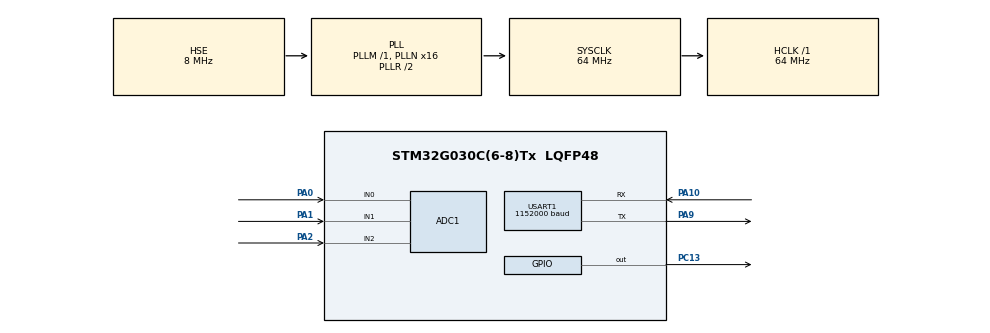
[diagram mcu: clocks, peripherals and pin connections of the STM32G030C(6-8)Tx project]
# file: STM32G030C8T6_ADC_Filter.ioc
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ADC1.ContinuousConvMode=ENABLE
ADC1.DMAContinuousRequests=ENABLE
ADC1.NbrOfConversion=1
ADC1.NbrOfConversionFlag=0
ADC1.SamplingTimeCommon1=ADC_SAMPLETIME_79CYCLES_5
ADC1.SelectedChannel=ADC_CHANNEL_0|ADC_CHANNEL_1|ADC_CHANNEL_2|ADC_CHANNEL_TEMPSENSOR
ADC1.Sequencer=NOT_FULLY_CONFIGURABLE
ADC1.master=1
Dma.ADC1.0.Direction=DMA_PERIPH_TO_MEMORY
Dma.ADC1.0.EventEnable=DISABLE
Dma.ADC1.0.Instance=DMA1_Channel1
Dma.ADC1.0.MemDataAlignment=DMA_MDATAALIGN_WORD
Dma.ADC1.0.MemInc=DMA_MINC_ENABLE
Dma.ADC1.0.Mode=DMA_CIRCULAR
Dma.ADC1.0.PeriphDataAlignment=DMA_PDATAALIGN_WORD
Dma.ADC1.0.PeriphInc=DMA_PINC_DISABLE
Dma.ADC1.0.Polarity=HAL_DMAMUX_REQ_GEN_RISING
Dma.ADC1.0.Priority=DMA_PRIORITY_LOW
Dma.ADC1.0.RequestNumber=1
Dma.ADC1.0.SignalID=NONE
Dma.ADC1.0.SyncEnable=DISABLE
Dma.ADC1.0.SyncPolarity=HAL_DMAMUX_SYNC_NO_EVENT
Dma.ADC1.0.SyncRequestNumber=1
Dma.ADC1.0.SyncSignalID=NONE
Dma.Request0=ADC1
Mcu.Family=STM32G0
Mcu.Name=STM32G030C(6-8)Tx
Mcu.Package=LQFP48
NVIC.ADC1_IRQn=true\:0\:0\:false\:false\:true\:true\:true\:true
NVIC.DMA1_Channel1_IRQn=true\:0\:0\:false\:false\:true\:false\:true\:true
PA0.Mode=IN0
PA0.Signal=ADC1_IN0
PA1.Mode=IN1
PA1.Signal=ADC1_IN1
PA10.Mode=Asynchronous
PA10.Signal=USART1_RX
PA13.Mode=Serial_Wire
PA13.Signal=SYS_SWDIO
PA14-BOOT0.Mode=Serial_Wire
PA14-BOOT0.Signal=SYS_SWCLK
PA2.Mode=IN2
PA2.Signal=ADC1_IN2
PA9.Mode=Asynchronous
PA9.Signal=USART1_TX
PC13.PinState=GPIO_PIN_SET
PC13.Signal=GPIO_Output
PF0-OSC_IN\ (PF0).Mode=HSE-External-Oscillator
PF0-OSC_IN\ (PF0).Signal=RCC_OSC_IN
PF1-OSC_OUT\ (PF1).Mode=HSE-External-Oscillator
PF1-OSC_OUT\ (PF1).Signal=RCC_OSC_OUT
ProjectManager.HeapSize=0x200
ProjectManager.StackSize=0x400
ProjectManager.TargetToolchain=Makefile
RCC.ADCFreq_Value=64000000
RCC.AHBFreq_Value=64000000
RCC.CortexFreq_Value=64000000
RCC.DATA_CACHE_ENABLE=1
RCC.EXTERNAL_CLOCK_VALUE=12288000
RCC.HCLKFreq_Value=64000000
RCC.HSE_VALUE=8000000
RCC.HSI_VALUE=16000000
RCC.INSTRUCTION_CACHE_ENABLE=1
RCC.LSE_VALUE=32768
RCC.PLLN=16
RCC.PLLSourceVirtual=RCC_PLLSOURCE_HSE
RCC.PREFETCH_ENABLE=1
RCC.SYSCLKFreq_VALUE=64000000
RCC.SYSCLKSource=RCC_SYSCLKSOURCE_PLLCLK
RCC.VCOOutputFreq_Value=128000000
USART1.BaudRate=1152000
USART1.VirtualMode-Asynchronous=VM_ASYNC
VP_ADC1_TempSens_Input.Mode=IN-TempSens
board=custom

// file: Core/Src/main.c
/* USER CODE BEGIN Header */
/**
  ******************************************************************************
  * @file           : main.c
  * @brief          : Main program body
  ******************************************************************************
  * @attention
  *
  * Copyright (c) 2022 STMicroelectronics.
  * All rights reserved.
  *
  * This software is licensed under terms that can be found in the LICENSE file
  * in the root directory of this software component.
  * If no LICENSE file comes with this software, it is provided AS-IS.
  *
  ******************************************************************************
  */
/* USER CODE END Header */
#include "main.h"
#include "adc.h"
#include "dma.h"
#include "usart.h"
#include "gpio.h"

/* USER CODE BEGIN Includes */
#include <math.h>
/* USER CODE END Includes */

/* USER CODE BEGIN PV */

float RF_Power_Fwd=0;

uint32_t ADC_Origin_Result[4]={0};
uint32_t ADC_Kalman_Result[4]={0};
/* USER CODE END PV */

void SystemClock_Config(void);

int main(void)
{

  /* MCU Configuration--------------------------------------------------------*/

  /* Reset of all peripherals, Initializes the Flash interface and the Systick. */
  HAL_Init();

  /* Configure the system clock */
  SystemClock_Config();

  /* Initialize all configured peripherals */
  MX_GPIO_Init();
  MX_DMA_Init();
  MX_ADC1_Init();
  MX_USART1_UART_Init();
  /* USER CODE BEGIN 2 */
  HAL_ADCEx_Calibration_Start(&hadc1);
  HAL_ADC_Start_DMA(&hadc1,ADC_Origin_Result,4);
  /* USER CODE END 2 */

  /* Infinite loop */
  while (1)
  {

  }
}

void SystemClock_Config(void)
{
  RCC_OscInitTypeDef RCC_OscInitStruct = {0};
  RCC_ClkInitTypeDef RCC_ClkInitStruct = {0};

  /** Configure the main internal regulator output voltage
  */
  HAL_PWREx_ControlVoltageScaling(PWR_REGULATOR_VOLTAGE_SCALE1);

  /** Initializes the RCC Oscillators according to the specified parameters
  * in the RCC_OscInitTypeDef structure.
  */
  RCC_OscInitStruct.OscillatorType = RCC_OSCILLATORTYPE_HSE;
  RCC_OscInitStruct.HSEState = RCC_HSE_ON;
  RCC_OscInitStruct.PLL.PLLState = RCC_PLL_ON;
  RCC_OscInitStruct.PLL.PLLSource = RCC_PLLSOURCE_HSE;
  RCC_OscInitStruct.PLL.PLLM = RCC_PLLM_DIV1;
  RCC_OscInitStruct.PLL.PLLN = 16;
  RCC_OscInitStruct.PLL.PLLP = RCC_PLLP_DIV2;
  RCC_OscInitStruct.PLL.PLLR = RCC_PLLR_DIV2;
  if (HAL_RCC_OscConfig(&RCC_OscInitStruct) != HAL_OK)
  {
    Error_Handler();
  }

  /** Initializes the CPU, AHB and APB buses clocks
  */
  RCC_ClkInitStruct.ClockType = RCC_CLOCKTYPE_HCLK|RCC_CLOCKTYPE_SYSCLK
                              |RCC_CLOCKTYPE_PCLK1;
  RCC_ClkInitStruct.SYSCLKSource = RCC_SYSCLKSOURCE_PLLCLK;
  RCC_ClkInitStruct.AHBCLKDivider = RCC_SYSCLK_DIV1;
  RCC_ClkInitStruct.APB1CLKDivider = RCC_HCLK_DIV1;

  if (HAL_RCC_ClockConfig(&RCC_ClkInitStruct, FLASH_LATENCY_2) != HAL_OK)
  {
    Error_Handler();
  }
}

/* USER CODE BEGIN 4 */
void HAL_ADC_ConvCpltCallback(ADC_HandleTypeDef *hadc){
  if(Filter(ADC_Origin_Result[2],&ADC_Kalman_Result[2]))
    HAL_GPIO_TogglePin(GPIOC,GPIO_PIN_13);
    RF_Power_Fwd=pow(2.71828,((ADC_Kalman_Result[2]-2010.3)/92.108));
        printf("Power_forward:%.2fW\r\n",RF_Power_Fwd);
    //printf("ADC:%ld,%ld\r\n",ADC_Kalman_Result[2],ADC_Origin_Result[2]);

}
/* USER CODE END 4 */

void Error_Handler(void)
{
  __disable_irq();
  while (1)
  {
  }
}
